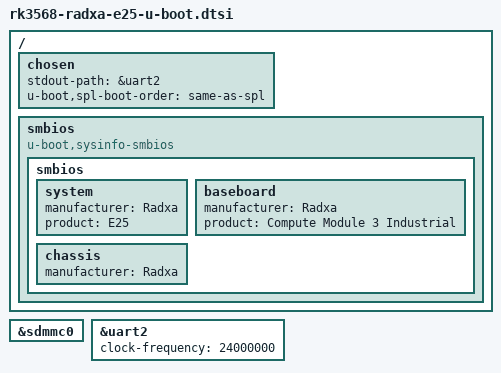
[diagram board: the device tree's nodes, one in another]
// SPDX-License-Identifier: GPL-2.0+
/*
 * (C) Copyright 2021 Rockchip Electronics Co., Ltd
 */

#include "rk3568-radxa-cm3i-u-boot.dtsi"

/ {
	chosen {
		stdout-path = &uart2;
		u-boot,spl-boot-order = "same-as-spl", &sdmmc0, &sdhci;
	};

	smbios {
		compatible = "u-boot,sysinfo-smbios";

		smbios {
			system {
				manufacturer = "Radxa";
				product = "E25";
			};

			baseboard {
				manufacturer = "Radxa";
				product = "Compute Module 3 Industrial";
			};

			chassis {
				manufacturer = "Radxa";
			};
		};
	};

};

&sdmmc0 {
	status = "okay";
};

&uart2 {
	clock-frequency = <24000000>;
	u-boot,dm-spl;
	status = "okay";
};
